# USB3_PHY_TX register map
Vendor: Texas Instruments
Peripheral module from a debugger description file (folder omap5430_ES2_PUBLIC).
Registers are 32-bit, access per field, reset 0x0 unless marked. A register's access mark holds for its fields unless they carry their own. Offsets are as the file gives them; lines under a group give offsets from that group; [hi:lo] are bit positions; {n}, {i} and the like mark numbered series; 'fields as' and 'values as' point back to an identical list; <NAME> marks a mode.

## USB3_PHY_TX
0x0C USB3PHYTX_FUNC_CONFIG_REG — Functional Configuration registers
  [31] MEM_INVPAIR rw — Invert polarity of TXP/TXN
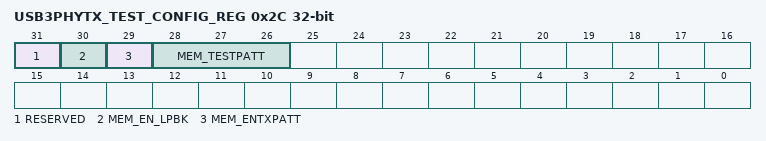
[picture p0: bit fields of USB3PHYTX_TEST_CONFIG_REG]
0x2C USB3PHYTX_TEST_CONFIG_REG — Test related configuration registers
  [31] RESERVED ro — Keep at 0
  [30] MEM_EN_LPBK rw — Loopback enable for test
  [29] MEM_ENTXPATT rw — Enable Test pattern to input of the serializer instead of TD
  [28:26] MEM_TESTPATT rw — Select the LFSR mode to generate the required pattern 000=&gt; 31 bit LFSR mode 011 =&gt; 23 bit LFSR mode 010 =&gt; 7 bit LFSR mode 001=&gt; generate 1010 pattern 100=&gt; Fixed 31 bit value from pattgen_preload_val
0x30 USB3PHYTX_PATTGEN_PRELOAD rw — Pattern generator (31 bit) LFSR Seed or preload value
  [31:1] MEM_PATTGEN_PRELOAD_VAL — Preload value to the LFSR pattern generator
